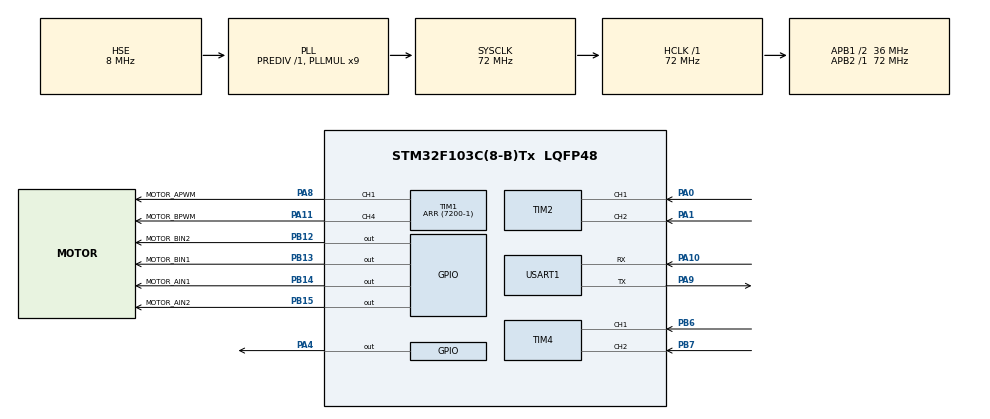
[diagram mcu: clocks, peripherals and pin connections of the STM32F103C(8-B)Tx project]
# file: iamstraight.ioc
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Mcu.Family=STM32F1
Mcu.Name=STM32F103C(8-B)Tx
Mcu.Package=LQFP48
NVIC.PriorityGroup=NVIC_PRIORITYGROUP_4
PA0-WKUP.Signal=S_TIM2_CH1_ETR
PA1.Signal=S_TIM2_CH2
PA10.Mode=Asynchronous
PA10.Signal=USART1_RX
PA11.GPIO_Label=MOTOR_BPWM
PA11.GPIO_Speed=GPIO_SPEED_FREQ_HIGH
PA11.Signal=S_TIM1_CH4
PA13.Mode=Serial_Wire
PA13.Signal=SYS_JTMS-SWDIO
PA14.Mode=Serial_Wire
PA14.Signal=SYS_JTCK-SWCLK
PA4.GPIO_Speed=GPIO_SPEED_FREQ_LOW
PA4.PinState=GPIO_PIN_SET
PA4.Signal=GPIO_Output
PA8.GPIO_Label=MOTOR_APWM
PA8.GPIO_Speed=GPIO_SPEED_FREQ_HIGH
PA8.Signal=S_TIM1_CH1
PA9.Mode=Asynchronous
PA9.Signal=USART1_TX
PB12.GPIO_Label=MOTOR_BIN2
PB12.GPIO_Speed=GPIO_SPEED_FREQ_HIGH
PB12.Signal=GPIO_Output
PB13.GPIO_Label=MOTOR_BIN1
PB13.GPIO_Speed=GPIO_SPEED_FREQ_HIGH
PB13.PinState=GPIO_PIN_RESET
PB13.Signal=GPIO_Output
PB14.GPIO_Label=MOTOR_AIN1
PB14.GPIO_Speed=GPIO_SPEED_FREQ_HIGH
PB14.Signal=GPIO_Output
PB15.GPIO_Label=MOTOR_AIN2
PB15.GPIO_Speed=GPIO_SPEED_FREQ_HIGH
PB15.Signal=GPIO_Output
PB6.Signal=S_TIM4_CH1
PB7.Signal=S_TIM4_CH2
PD0-OSC_IN.Mode=HSE-External-Oscillator
PD0-OSC_IN.Signal=RCC_OSC_IN
PD1-OSC_OUT.Mode=HSE-External-Oscillator
PD1-OSC_OUT.Signal=RCC_OSC_OUT
ProjectManager.HeapSize=0x200
ProjectManager.StackSize=0x400
ProjectManager.TargetToolchain=Makefile
RCC.AHBFreq_Value=72000000
RCC.APB1CLKDivider=RCC_HCLK_DIV2
RCC.APB1Freq_Value=36000000
RCC.APB1TimFreq_Value=72000000
RCC.APB2Freq_Value=72000000
RCC.APB2TimFreq_Value=72000000
RCC.HCLKFreq_Value=72000000
RCC.PLLMUL=RCC_PLL_MUL9
RCC.PLLSourceVirtual=RCC_PLLSOURCE_HSE
RCC.SYSCLKFreq_VALUE=72000000
RCC.SYSCLKSource=RCC_SYSCLKSOURCE_PLLCLK
RCC.USBFreq_Value=72000000
SH.S_TIM1_CH1.0=TIM1_CH1,PWM Generation1 CH1
SH.S_TIM1_CH4.0=TIM1_CH4,PWM Generation4 CH4
SH.S_TIM2_CH1_ETR.0=TIM2_CH1,Encoder_Interface
SH.S_TIM2_CH2.0=TIM2_CH2,Encoder_Interface
SH.S_TIM4_CH1.0=TIM4_CH1,Encoder_Interface
SH.S_TIM4_CH2.0=TIM4_CH2,Encoder_Interface
TIM1.Channel-PWM\ Generation1\ CH1=TIM_CHANNEL_1
TIM1.Channel-PWM\ Generation4\ CH4=TIM_CHANNEL_4
TIM1.Period=(7200-1)
TIM1.TIM_MasterOutputTrigger=TIM_TRGO_RESET
TIM2.EncoderMode=TIM_ENCODERMODE_TI12
TIM4.EncoderMode=TIM_ENCODERMODE_TI12
USART1.VirtualMode=VM_ASYNC
VP_TIM1_VS_ClockSourceINT.Mode=Internal
board=custom

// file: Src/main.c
/* USER CODE BEGIN Header */
/**
  ******************************************************************************
  * @file           : main.c
  * @brief          : Main program body
  ******************************************************************************
  * @attention
  *
  * Copyright (c) 2023 STMicroelectronics.
  * All rights reserved.
  *
  * This software is licensed under terms that can be found in the LICENSE file
  * in the root directory of this software component.
  * If no LICENSE file comes with this software, it is provided AS-IS.
  *
  ******************************************************************************
  */
/* USER CODE END Header */
#include "main.h"
#include "tim.h"
#include "usart.h"
#include "gpio.h"

/* USER CODE BEGIN Includes */
#include "stdio.h"

#include "led.h"
/* USER CODE END Includes */

void SystemClock_Config(void);

int main(void)
{

  /* MCU Configuration--------------------------------------------------------*/

  /* Reset of all peripherals, Initializes the Flash interface and the Systick. */
  HAL_Init();

  /* Configure the system clock */
  SystemClock_Config();

  /* Initialize all configured peripherals */
  MX_GPIO_Init();
  MX_USART1_UART_Init();
  MX_TIM1_Init();
  MX_TIM2_Init();
  MX_TIM4_Init();
  /* USER CODE BEGIN 2 */
  HAL_TIM_Encoder_Start(&htim2, TIM_CHANNEL_1);
  HAL_TIM_Encoder_Start(&htim2, TIM_CHANNEL_2);
  HAL_TIM_Encoder_Start(&htim4, TIM_CHANNEL_1);
  HAL_TIM_Encoder_Start(&htim4, TIM_CHANNEL_2);
  /* USER CODE END 2 */

  /* Infinite loop */
  /* USER CODE BEGIN WHILE */
  while (1)
  {
     HAL_Delay(100);
     BSP_LED_Toggle(LED_BLUE);

    /* USER CODE END WHILE */

  }
}

void SystemClock_Config(void)
{
  RCC_OscInitTypeDef RCC_OscInitStruct = {0};
  RCC_ClkInitTypeDef RCC_ClkInitStruct = {0};

  /** Initializes the RCC Oscillators according to the specified parameters
  * in the RCC_OscInitTypeDef structure.
  */
  RCC_OscInitStruct.OscillatorType = RCC_OSCILLATORTYPE_HSE;
  RCC_OscInitStruct.HSEState = RCC_HSE_ON;
  RCC_OscInitStruct.HSEPredivValue = RCC_HSE_PREDIV_DIV1;
  RCC_OscInitStruct.HSIState = RCC_HSI_ON;
  RCC_OscInitStruct.PLL.PLLState = RCC_PLL_ON;
  RCC_OscInitStruct.PLL.PLLSource = RCC_PLLSOURCE_HSE;
  RCC_OscInitStruct.PLL.PLLMUL = RCC_PLL_MUL9;
  if (HAL_RCC_OscConfig(&RCC_OscInitStruct) != HAL_OK)
  {
    Error_Handler();
  }

  /** Initializes the CPU, AHB and APB buses clocks
  */
  RCC_ClkInitStruct.ClockType = RCC_CLOCKTYPE_HCLK|RCC_CLOCKTYPE_SYSCLK
                              |RCC_CLOCKTYPE_PCLK1|RCC_CLOCKTYPE_PCLK2;
  RCC_ClkInitStruct.SYSCLKSource = RCC_SYSCLKSOURCE_PLLCLK;
  RCC_ClkInitStruct.AHBCLKDivider = RCC_SYSCLK_DIV1;
  RCC_ClkInitStruct.APB1CLKDivider = RCC_HCLK_DIV2;
  RCC_ClkInitStruct.APB2CLKDivider = RCC_HCLK_DIV1;

  if (HAL_RCC_ClockConfig(&RCC_ClkInitStruct, FLASH_LATENCY_2) != HAL_OK)
  {
    Error_Handler();
  }
}

void Error_Handler(void)
{
  __disable_irq();
  while (1)
  {
  }
}
